AUTOSAR XML (schema 00045)
package /ModM_Package
  client server interface CSI_ModM_OperationMode
    operation currentmode: fire-and-forget=false, possible-error=[E_NOT_OK, E_OK]
      arg mode: type=uint8_t, direction=OUT, server-argument-impl-policy=USE-ARGUMENT-TYPE
    operation nextmode: fire-and-forget=false, possible-error=[E_NOT_OK, E_OK]
      arg mode: type=uint8_t, direction=OUT, server-argument-impl-policy=USE-ARGUMENT-TYPE
    error E_NOT_OK: error-code=1
    error E_OK: error-code=0
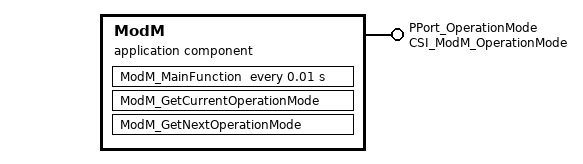
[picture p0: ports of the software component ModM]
  application sw component type ModM  # Ecu Mode Management | The Software shall implement Ecu Operation Mode switch according switch condition.
    provide port PPort_OperationMode: provided-com-specs=[{operation=currentmode, queue-length=1}, {operation=nextmode, queue-length=1}], provided-interface=CSI_ModM_OperationMode
    behavior ModM_IB: handle-termination-and-restart=NO-SUPPORT
      timing event TE_ModM_MainFunction: start-on-event=ModM_MainFunction, period=0.01
      operation invoked event oie_PPort_OperationMode_currentmode: start-on-event=ModM_GetCurrentOperationMode, operation=PPort_OperationMode.currentmode
      operation invoked event oie_PPort_OperationMode_nextmode: start-on-event=ModM_GetNextOperationMode, operation=PPort_OperationMode.nextmode
      runnable ModM_GetCurrentOperationMode
      runnable ModM_GetNextOperationMode
      runnable ModM_MainFunction
  swc implementation ModM_Impl: programming-language=C, sw-version=1.0.0, vendor-id=0, behavior=ModM_IB
    code-descriptors:
      code CD_ModM: artifact-descriptors=[{short-label=SWHDR, category=SWHDR}, {short-label=SWSRC, category=SWSRC}]
    resource consumption Resource
      5 x memory section:
        CODE: sw-addrmethod=CODE
        CODE_LOCAL: options=coreLocal, sw-addrmethod=CODE_LOCAL
        CONST: sw-addrmethod=CONST
        VAR_CLEARED_LOCAL: options=coreLocal, sw-addrmethod=VAR_CLEARED_LOCAL
        VAR_INIT_LOCAL: options=coreLocal, sw-addrmethod=VAR_CLEARED_LOCAL
